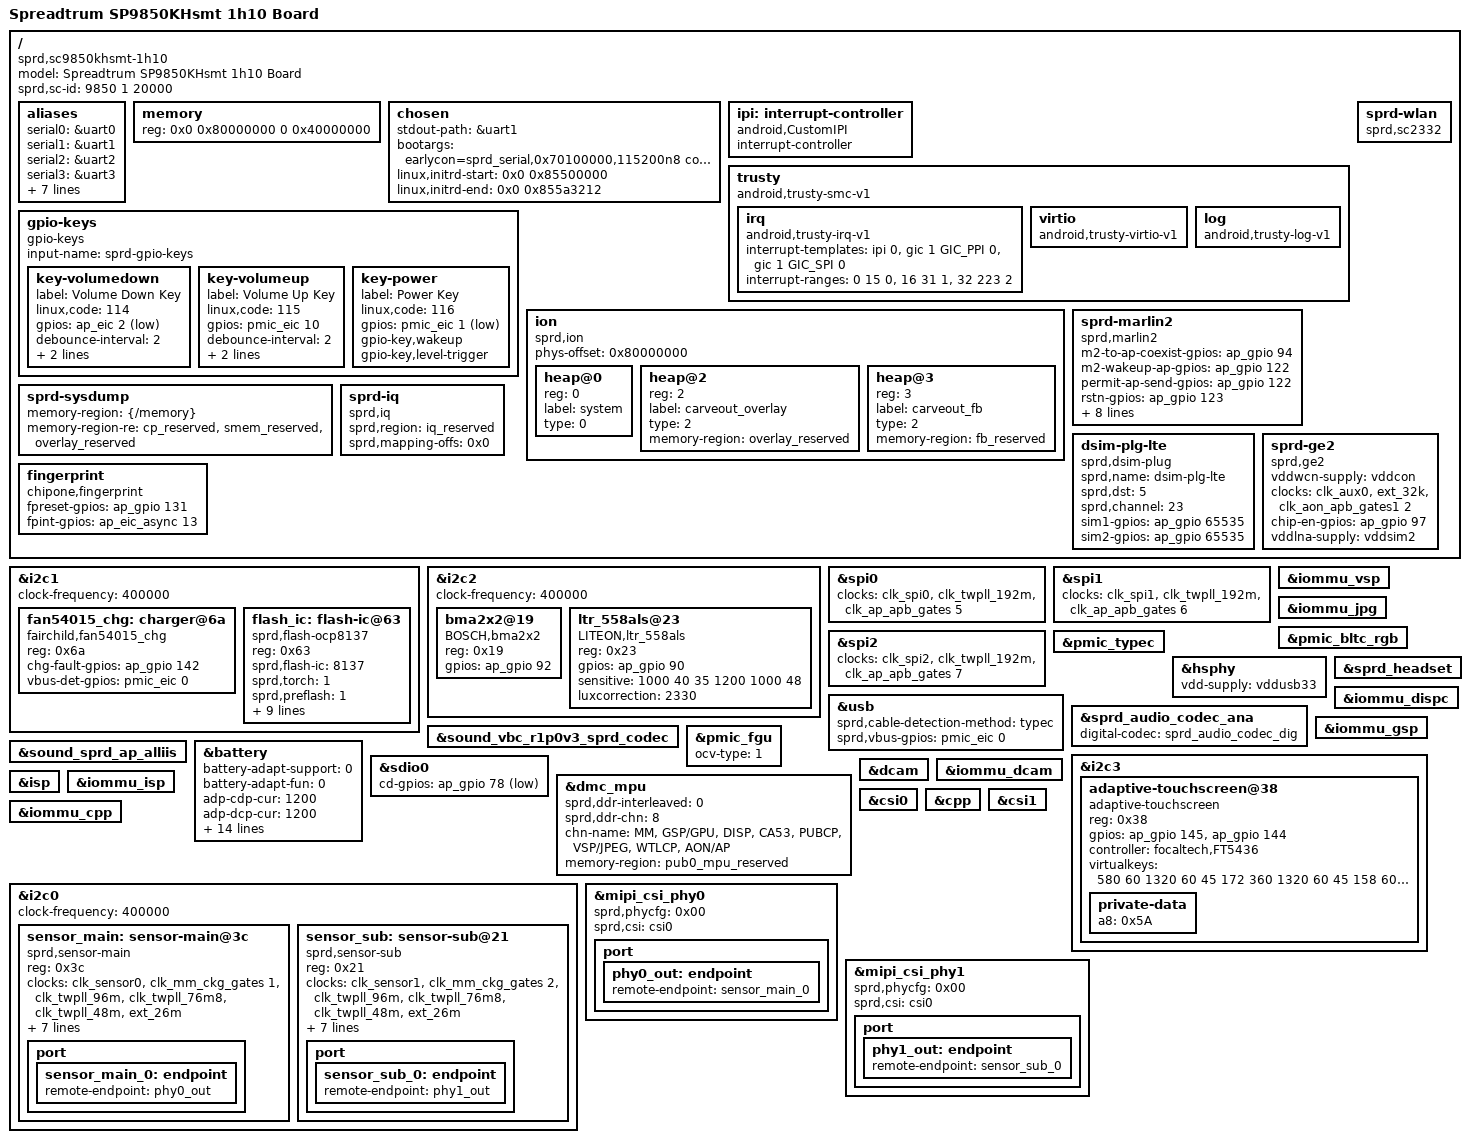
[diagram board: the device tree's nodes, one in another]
/*
 * Spreadtrum SP9850KH board DTS file
 *
 * Copyright (C) 2016, Spreadtrum Communications Inc.
 *
 * This file is licensed under a dual GPLv2 or X11 license.
 */

/dts-v1/;

#include "sc9850khsmt.dtsi"
#include "sp9850kh-common.dtsi"

/ {
	model = "Spreadtrum SP9850KHsmt 1h10 Board";

	compatible = "sprd,sc9850khsmt-1h10";

	sprd,sc-id = <9850 1 20000>;

	aliases {
		serial0 = &uart0;
		serial1 = &uart1;
		serial2 = &uart2;
		serial3 = &uart3;
		i2c0 = &i2c0;
		i2c1 = &i2c1;
		i2c2 = &i2c2;
		i2c3 = &i2c3;
		spi0 = &spi0;
		spi1 = &spi1;
		spi2 = &spi2;
	};

	memory{
		device_type = "memory";
		reg = <0x0 0x80000000 0 0x40000000>;
	};

	chosen {
		stdout-path = &uart1;
		bootargs = "earlycon=sprd_serial,0x70100000,115200n8 console=ttyS1,115200n8 loglevel=1 androidboot.hardware=sp9850kh_1h10 memblock=debug bootmem_debug=1";
		linux,initrd-start = <0x0 0x85500000>; /* this val will be changed by uboot  */
		linux,initrd-end = <0x0 0x855a3212>; /* this val will be changed by uboot  */
	};

	ipi: interrupt-controller {
		compatible = "android,CustomIPI";
		#interrupt-cells = <1>;
		interrupt-controller;
	};

	trusty {
		compatible = "android,trusty-smc-v1";

		irq {
			compatible = "android,trusty-irq-v1";
			interrupt-templates = <&ipi 0>,
						<&gic 1 GIC_PPI 0>,
						<&gic 1 GIC_SPI 0>;
			interrupt-ranges = < 0  15 0>,
						<16  31 1>,
						<32 223 2>;
		};

		virtio {
			compatible = "android,trusty-virtio-v1";
		};

		log {
			compatible = "android,trusty-log-v1";
		};
	};

	gpio-keys {
		compatible = "gpio-keys";
		input-name = "sprd-gpio-keys";
		status = "okay";

		key-volumedown {
			label = "Volume Down Key";
			linux,code = <114>;
			gpios = <&ap_eic 2 1>;
			debounce-interval = <2>;
			gpio-key,wakeup;
			gpio-key,level-trigger;
		};

		key-volumeup {
			label = "Volume Up Key";
			linux,code = <115>;
			gpios = <&pmic_eic 10 0>;
			debounce-interval = <2>;
			gpio-key,wakeup;
			gpio-key,level-trigger;
		};

		key-power {
			label = "Power Key";
			linux,code = <116>;
			gpios = <&pmic_eic 1 1>;
			gpio-key,wakeup;
			gpio-key,level-trigger;
		};
	};

	ion {
		compatible = "sprd,ion";
		#address-cells = <1>;
		#size-cells = <0>;
		phys-offset = <0x80000000>;

		heap@0 {
			reg = <0>;
			label = "system";
			type = <0>;
		};

		heap@2 {
			reg = <2>;
			label = "carveout_overlay";
			type = <2>;
			memory-region = <&overlay_reserved>;
		};

		heap@3 {
			reg = <3>;
			label = "carveout_fb";
			type = <2>;
			memory-region = <&fb_reserved>;
		};
	};

	sprd-marlin2 {
		compatible = "sprd,marlin2";
		m2-to-ap-coexist-gpios = <&ap_gpio 94 0>;
		m2-wakeup-ap-gpios = <&ap_gpio 122 0>;
		permit-ap-send-gpios = <&ap_gpio 122 0>;
		rstn-gpios = <&ap_gpio 123 0>;
		chip-en-gpios = <&ap_gpio 97 0>;
		m2-to-ap-irq-gpios = <&ap_gpio 121 0>;
		vddwcn-supply = <&vddcon>;
		clock-names = "clk_32k","source","enable";
		clocks = <&clk_aux0>,<&ext_32k>,
			 <&clk_aon_apb_gates1 2>;
		sdhci-name = <&sdio1>;
		common_chip_en;
		power-ctl-disabled;
	};

	sprd-sysdump {
		memory-region = <&{/memory}>;
		memory-region-re = <&cp_reserved>, <&smem_reserved>,
				   <&overlay_reserved>;
	};

	sprd-wlan {
		compatible = "sprd,sc2332";
	};

	sprd-iq {
		compatible = "sprd,iq";
		sprd,region = <&iq_reserved>;
		sprd,mapping-offs = <0x0>;
	};

	dsim-plg-lte {
		compatible = "sprd,dsim-plug";
		sprd,name = "dsim-plg-lte";
		sprd,dst = <5>;
		sprd,channel = <23>;
		sim1-gpios = <&ap_gpio 65535 0>;
		sim2-gpios = <&ap_gpio 65535 0>;
	};

	sprd-ge2 {
		compatible = "sprd,ge2";
		vddwcn-supply = <&vddcon>;
		clock-names = "clk_32k","source","enable";
		clocks = <&clk_aux0>,<&ext_32k>,
			 <&clk_aon_apb_gates1 2>;
		chip-en-gpios = <&ap_gpio 97 0>;
		vddlna-supply = <&vddsim2>;
	};

	fingerprint {
		compatible = "chipone,fingerprint";
		fpreset-gpios = <&ap_gpio 131 0 >;
		fpint-gpios = <&ap_eic_async 13 0 >;
	};
};

&i2c1 {
	status = "okay";
	clock-frequency = <400000>;
	fan54015_chg: charger@6a {
		compatible = "fairchild,fan54015_chg";
		reg = <0x6a>;
		chg-fault-gpios = <&ap_gpio 142 0>;
		vbus-det-gpios = <&pmic_eic 0 0>;
	};

	flash_ic: flash-ic@63 {
		compatible = "sprd,flash-ocp8137";
		reg = <0x63>;
		sprd,flash-ic = <8137>;
		sprd,torch = <1>;
		sprd,preflash = <1>;
		sprd,highlight = <1>;
		sprd,torch-level = <128>;
		sprd,preflash-level = <128>;
		sprd,highlight-level = <128>;
		sprd,lvfm-enable = <1>;
		flash-torch-en-gpios = <&ap_gpio 87 0>;
		flash-chip-en-gpios = <&ap_gpio 89 0>;
		flash-en-gpios = <&ap_gpio 31 0>;
		flash-sync-gpios = <&ap_gpio 30 0>;
	};
};

&i2c2 {
	status = "okay";
	clock-frequency = <400000>;
	bma2x2@19{
		compatible = "BOSCH,bma2x2";
		reg = <0x19>;
		gpios = <&ap_gpio 92 0>;
	};

	ltr_558als@23{
		compatible = "LITEON,ltr_558als";
		reg = <0x23>;
		gpios = <&ap_gpio 90 0>;
		sensitive = <1000 40 35
					1200 1000 48>;
		luxcorrection = <2330>;
	};
};

&spi0 {
	clocks = <&clk_spi0>, <&clk_twpll_192m>,
		<&clk_ap_apb_gates 5>;
};

&spi1 {
	clocks = <&clk_spi1>, <&clk_twpll_192m>,
		<&clk_ap_apb_gates 6>;
};

&spi2 {
	/*used for fingerprint sensor*/
	clocks = <&clk_spi2>, <&clk_twpll_192m>,
		<&clk_ap_apb_gates 7>;
	status = "okay";
};

&iommu_vsp {
	    status = "okay";
};

&iommu_jpg {
	status = "okay";
};

&pmic_bltc_rgb {
	status = "okay";
};

&pmic_typec {
	status = "okay";
};

&hsphy {
	vdd-supply = <&vddusb33>;
};

&usb {
	sprd,cable-detection-method = "typec";
	sprd,vbus-gpios = <&pmic_eic 0 0>;
};

&sprd_audio_codec_ana {
	status = "okay";
	digital-codec = <&sprd_audio_codec_dig>;
};

&sprd_headset {
	status = "okay";
};

&sound_vbc_r1p0v3_sprd_codec {
	status = "okay";
};

&sound_sprd_ap_alliis {
	status = "okay";
};

&iommu_dispc {
	status = "okay";
};

&iommu_gsp {
	status = "okay";
};

&i2c3 {
	status = "okay";
	adaptive-touchscreen@38 {
		compatible = "adaptive-touchscreen";
		reg = <0x38>;
		gpios = <&ap_gpio 145 0
			&ap_gpio 144 0>;
		controller = "focaltech,FT5436";
		virtualkeys = <580 60 1320 60 45
				   172 360 1320 60 45
				   158 600 1320 60 45>;
		private-data {
			a8 = /bits/ 8 <0x5A>;
		};
	};
};

&battery {
	battery-adapt-support = <0>;
	battery-adapt-fun = <0>;
	adp-cdp-cur = <1200>;
	adp-dcp-cur = <1200>;
	adp-sdp-cur = <550>;
	adp-unknown-cur = <550>;
	chg-end-vol = <4350>;
	chg-end-vol-check = <4330>;
	chg-bat-safety-vol = <4430>;
	rechg-vol = <4270>;
	rsense-real = <200>;
	rint = <320>;
	cnom = <2780>;
	chg-polling-time = <10>;
	ocv-tab-vol = <4340 4243 4185 4132 4083 4037 3996
			3959 3921 3876 3842 3818 3800 3786
			3776 3768 3753 3731 3696 3663 3400>;
	ocv-tab-cap = <100  95   90   85   80   75   70
			65   60   55   50   45   40   35
			30   25   20   15   10   5    0>;
};

&pmic_fgu {
	ocv-type = <1>;
};

&sdio0 {
	cd-gpios = <&ap_gpio 78 1>;
};

&dmc_mpu {
	sprd,ddr-interleaved = <0>;
	sprd,ddr-chn = <8>;
	chn-name = "MM", "GSP/GPU", "DISP",
			"CA53", "PUBCP", "VSP/JPEG",
			"WTLCP", "AON/AP";
	memory-region = <&pub0_mpu_reserved>;
};

&dcam {
	status = "okay";
};

&iommu_dcam {
	status = "okay";
};

&isp {
	status = "okay";
};

&iommu_isp {
	status = "okay";
};

&csi0 {
	status = "okay";
};

&cpp {
	status = "okay";
};

&iommu_cpp {
	status = "okay";
};

&csi1 {
	status = "okay";
};

&i2c0 {
	status = "okay";
	clock-frequency = <400000>;

	sensor_main: sensor-main@3c {
		compatible = "sprd,sensor-main";
		reg = <0x3c>;
		clock-names = "clk_src", "sensor_eb",
			"clk_96m", "clk_76m8",
			"clk_48m", "clk_26m";
		clocks  = <&clk_sensor0>,
			<&clk_mm_ckg_gates 1>,
			<&clk_twpll_96m>,
			<&clk_twpll_76m8>,
			<&clk_twpll_48m>,
			<&ext_26m>;
		vddio-supply = <&vddcamio>;
		vddcama-supply = <&vddcama>;
		vddcamd-supply = <&vddcamd>;
		vddcammot-supply = <&vddcammot>;
		reset-gpios = <&ap_gpio 44 0>;
		power-down-gpios = <&ap_gpio 46 0>;
		host = "dcam0";
		port {
			sensor_main_0: endpoint {
				remote-endpoint = <&phy0_out>;
			};
		};
	};

	sensor_sub: sensor-sub@21 {
		compatible = "sprd,sensor-sub";
		reg = <0x21>;
		clock-names = "clk_src","sensor_eb",
			"clk_96m", "clk_76m8",
			"clk_48m", "clk_26m";
		clocks = <&clk_sensor1>,
			<&clk_mm_ckg_gates 2>,
			<&clk_twpll_96m>,
			<&clk_twpll_76m8>,
			<&clk_twpll_48m>,
			<&ext_26m>;
		vddio-supply = <&vddcamio>;
		vddcama-supply = <&vddcama>;
		vddcamd-supply = <&vddcamd>;
		vddcammot-supply = <&vddcammot>;
		reset-gpios = <&ap_gpio 45 0>;
		power-down-gpios = <&ap_gpio 47 0>;
		host = "dcam0";
		port {
			sensor_sub_0: endpoint {
				remote-endpoint = <&phy1_out>;
			};
		};
	};
};

&mipi_csi_phy0 {
	status = "okay";
	sprd,phycfg = <0x00>;
	sprd,csi = <&csi0>;
	port {
		phy0_out: endpoint {
			remote-endpoint = <&sensor_main_0>;
		};
	};
};

&mipi_csi_phy1 {
	status = "okay";
	sprd,phycfg = <0x00>;
	sprd,csi = <&csi0>;
	port {
		phy1_out: endpoint {
			remote-endpoint = <&sensor_sub_0>;
		};
	};
};

